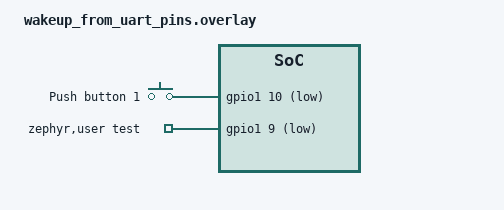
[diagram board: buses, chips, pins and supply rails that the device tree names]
/*
 * Copyright (c) 2024 Nordic Semiconductor ASA
 *
 * SPDX-License-Identifier: LicenseRef-Nordic-5-Clause
 */

/ {
	/*
	 * Redefine sw1/button1 to use RXD1 - P1.10
	 * Thus, when sending character from host, there will be gpio interrupt,
	 * the same as originally triggered by sw1 button.
	 */
	aliases {
		sw1 = &button1;
	};

	buttons {
		compatible = "gpio-keys";

		button1: button_1 {
			gpios = <&gpio1 10 (GPIO_PULL_UP | GPIO_ACTIVE_LOW)>;
			label = "Push button 1";
			zephyr,code = <INPUT_KEY_1>;
		};
	};

	zephyr,user {
		test-gpios = <&gpio1 9 GPIO_ACTIVE_LOW>;
	};
};

&gpio1 {
	status = "okay";
};
